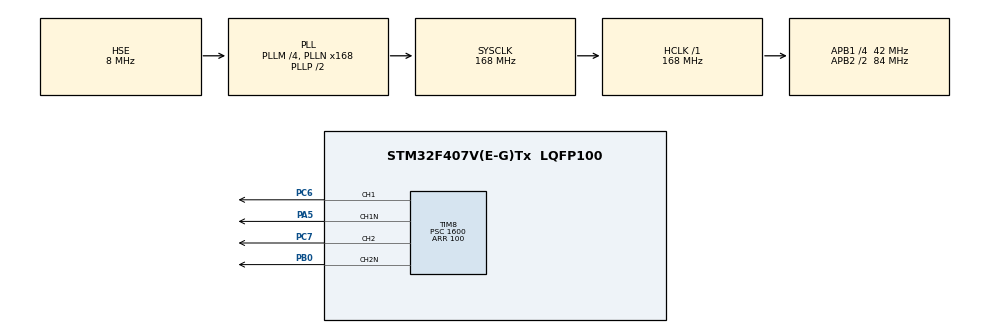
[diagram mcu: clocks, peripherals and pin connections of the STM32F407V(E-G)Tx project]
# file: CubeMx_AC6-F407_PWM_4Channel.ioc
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Mcu.Family=STM32F4
Mcu.Name=STM32F407V(E-G)Tx
Mcu.Package=LQFP100
NVIC.PriorityGroup=NVIC_PRIORITYGROUP_4
PA5.GPIO_Speed=GPIO_SPEED_FREQ_HIGH
PA5.Mode=PWM Generation1 CH1 CH1N
PA5.Signal=TIM8_CH1N
PB0.GPIO_Speed=GPIO_SPEED_FREQ_HIGH
PB0.Mode=PWM Generation2 CH2 CH2N
PB0.Signal=TIM8_CH2N
PC6.GPIO_Speed=GPIO_SPEED_FREQ_HIGH
PC6.Signal=S_TIM8_CH1
PC7.GPIO_Speed=GPIO_SPEED_FREQ_HIGH
PC7.Signal=S_TIM8_CH2
PH0-OSC_IN.Mode=HSE-External-Oscillator
PH0-OSC_IN.Signal=RCC_OSC_IN
PH1-OSC_OUT.Mode=HSE-External-Oscillator
PH1-OSC_OUT.Signal=RCC_OSC_OUT
ProjectManager.HeapSize=0x200
ProjectManager.StackSize=0x400
ProjectManager.TargetToolchain=SW4STM32
RCC.48MHZClocksFreq_Value=84000000
RCC.AHBFreq_Value=168000000
RCC.APB1CLKDivider=RCC_HCLK_DIV4
RCC.APB1Freq_Value=42000000
RCC.APB1TimFreq_Value=84000000
RCC.APB2CLKDivider=RCC_HCLK_DIV2
RCC.APB2Freq_Value=84000000
RCC.APB2TimFreq_Value=168000000
RCC.CortexFreq_Value=168000000
RCC.HCLKFreq_Value=168000000
RCC.HSE_VALUE=8000000
RCC.HSI_VALUE=16000000
RCC.LSE_VALUE=32768
RCC.PLLM=4
RCC.PLLN=168
RCC.PLLSourceVirtual=RCC_PLLSOURCE_HSE
RCC.SYSCLKFreq_VALUE=168000000
RCC.SYSCLKSource=RCC_SYSCLKSOURCE_PLLCLK
RCC.VCOOutputFreq_Value=336000000
SH.S_TIM8_CH1.0=TIM8_CH1,PWM Generation1 CH1 CH1N
SH.S_TIM8_CH2.0=TIM8_CH2,PWM Generation2 CH2 CH2N
TIM8.Channel-PWM\ Generation2\ CH2\ CH2N=TIM_CHANNEL_2
TIM8.DeadTime=255
TIM8.OCNPolarity_1=TIM_OCNPOLARITY_HIGH
TIM8.Period=100
TIM8.Prescaler=1600
TIM8.Pulse-PWM\ Generation1\ CH1\ CH1N=30
TIM8.Pulse-PWM\ Generation2\ CH2\ CH2N=80
board=CubeMx_AC6-F407_PWM_4Channel

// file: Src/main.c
/**
  ******************************************************************************
  * File Name          : main.c
  * Description        : Main program body
  ******************************************************************************
  *
  * COPYRIGHT(c) 2017 STMicroelectronics
  *
  * Redistribution and use in source and binary forms, with or without modification,
  * are permitted provided that the following conditions are met:
  *   1. Redistributions of source code must retain the above copyright notice,
  *      this list of conditions and the following disclaimer.
  *   2. Redistributions in binary form must reproduce the above copyright notice,
  *      this list of conditions and the following disclaimer in the documentation
  *      and/or other materials provided with the distribution.
  *   3. Neither the name of STMicroelectronics nor the names of its contributors
  *      may be used to endorse or promote products derived from this software
  *      without specific prior written permission.
  *
  * THIS SOFTWARE IS PROVIDED BY THE COPYRIGHT HOLDERS AND CONTRIBUTORS "AS IS"
  * AND ANY EXPRESS OR IMPLIED WARRANTIES, INCLUDING, BUT NOT LIMITED TO, THE
  * IMPLIED WARRANTIES OF MERCHANTABILITY AND FITNESS FOR A PARTICULAR PURPOSE ARE
  * DISCLAIMED. IN NO EVENT SHALL THE COPYRIGHT HOLDER OR CONTRIBUTORS BE LIABLE
  * FOR ANY DIRECT, INDIRECT, INCIDENTAL, SPECIAL, EXEMPLARY, OR CONSEQUENTIAL
  * DAMAGES (INCLUDING, BUT NOT LIMITED TO, PROCUREMENT OF SUBSTITUTE GOODS OR
  * SERVICES; LOSS OF USE, DATA, OR PROFITS; OR BUSINESS INTERRUPTION) HOWEVER
  * CAUSED AND ON ANY THEORY OF LIABILITY, WHETHER IN CONTRACT, STRICT LIABILITY,
  * OR TORT (INCLUDING NEGLIGENCE OR OTHERWISE) ARISING IN ANY WAY OUT OF THE USE
  * OF THIS SOFTWARE, EVEN IF ADVISED OF THE POSSIBILITY OF SUCH DAMAGE.
  *
  ******************************************************************************
  */
#include "main.h"
#include "stm32f4xx_hal.h"

TIM_HandleTypeDef htim8;

/* USER CODE BEGIN PV */
/* Private variables ---------------------------------------------------------*/

/* USER CODE END PV */

void SystemClock_Config(void);
void Error_Handler(void);
static void MX_GPIO_Init(void);
static void MX_TIM8_Init(void);
void HAL_TIM_MspPostInit(TIM_HandleTypeDef *htim);

/* USER CODE BEGIN PFP */
/* Private function prototypes -----------------------------------------------*/

/* USER CODE END PFP */

int main(void)
{

  /* MCU Configuration----------------------------------------------------------*/

  /* Reset of all peripherals, Initializes the Flash interface and the Systick. */
  HAL_Init();

  /* Configure the system clock */
  SystemClock_Config();

  /* Initialize all configured peripherals */
  MX_GPIO_Init();
  MX_TIM8_Init();

  /* USER CODE BEGIN 2 */

  HAL_TIM_PWM_Start(&htim8, TIM_CHANNEL_1);    //starts PWM on CH1 pin
  HAL_TIMEx_PWMN_Start(&htim8, TIM_CHANNEL_1); //starts PWM on CH1N pin
  HAL_TIM_PWM_Start(&htim8, TIM_CHANNEL_2);    //starts PWM on CH1 pin
  HAL_TIMEx_PWMN_Start(&htim8, TIM_CHANNEL_2); //starts PWM on CH1N pin

  /* USER CODE END 2 */

  /* Infinite loop */
  while (1)
  {

  }

}

/** System Clock Configuration
*/
void SystemClock_Config(void)
{

  RCC_OscInitTypeDef RCC_OscInitStruct;
  RCC_ClkInitTypeDef RCC_ClkInitStruct;

    /**Configure the main internal regulator output voltage
    */
  __HAL_RCC_PWR_CLK_ENABLE();

  __HAL_PWR_VOLTAGESCALING_CONFIG(PWR_REGULATOR_VOLTAGE_SCALE1);

    /**Initializes the CPU, AHB and APB busses clocks
    */
  RCC_OscInitStruct.OscillatorType = RCC_OSCILLATORTYPE_HSE;
  RCC_OscInitStruct.HSEState = RCC_HSE_ON;
  RCC_OscInitStruct.PLL.PLLState = RCC_PLL_ON;
  RCC_OscInitStruct.PLL.PLLSource = RCC_PLLSOURCE_HSE;
  RCC_OscInitStruct.PLL.PLLM = 4;
  RCC_OscInitStruct.PLL.PLLN = 168;
  RCC_OscInitStruct.PLL.PLLP = RCC_PLLP_DIV2;
  RCC_OscInitStruct.PLL.PLLQ = 4;
  if (HAL_RCC_OscConfig(&RCC_OscInitStruct) != HAL_OK)
  {
    Error_Handler();
  }

    /**Initializes the CPU, AHB and APB busses clocks
    */
  RCC_ClkInitStruct.ClockType = RCC_CLOCKTYPE_HCLK|RCC_CLOCKTYPE_SYSCLK
                              |RCC_CLOCKTYPE_PCLK1|RCC_CLOCKTYPE_PCLK2;
  RCC_ClkInitStruct.SYSCLKSource = RCC_SYSCLKSOURCE_PLLCLK;
  RCC_ClkInitStruct.AHBCLKDivider = RCC_SYSCLK_DIV1;
  RCC_ClkInitStruct.APB1CLKDivider = RCC_HCLK_DIV4;
  RCC_ClkInitStruct.APB2CLKDivider = RCC_HCLK_DIV2;

  if (HAL_RCC_ClockConfig(&RCC_ClkInitStruct, FLASH_LATENCY_5) != HAL_OK)
  {
    Error_Handler();
  }

    /**Configure the Systick interrupt time
    */
  HAL_SYSTICK_Config(HAL_RCC_GetHCLKFreq()/1000);

    /**Configure the Systick
    */
  HAL_SYSTICK_CLKSourceConfig(SYSTICK_CLKSOURCE_HCLK);

  /* SysTick_IRQn interrupt configuration */
  HAL_NVIC_SetPriority(SysTick_IRQn, 0, 0);
}

/* TIM8 init function */
static void MX_TIM8_Init(void)
{

  TIM_MasterConfigTypeDef sMasterConfig;
  TIM_OC_InitTypeDef sConfigOC;
  TIM_BreakDeadTimeConfigTypeDef sBreakDeadTimeConfig;

  htim8.Instance = TIM8;
  htim8.Init.Prescaler = 1600;
  htim8.Init.CounterMode = TIM_COUNTERMODE_UP;
  htim8.Init.Period = 100;
  htim8.Init.ClockDivision = TIM_CLOCKDIVISION_DIV1;
  htim8.Init.RepetitionCounter = 0;
  if (HAL_TIM_PWM_Init(&htim8) != HAL_OK)
  {
    Error_Handler();
  }

  sMasterConfig.MasterOutputTrigger = TIM_TRGO_RESET;
  sMasterConfig.MasterSlaveMode = TIM_MASTERSLAVEMODE_DISABLE;
  if (HAL_TIMEx_MasterConfigSynchronization(&htim8, &sMasterConfig) != HAL_OK)
  {
    Error_Handler();
  }

  sConfigOC.OCMode = TIM_OCMODE_PWM1;
  sConfigOC.Pulse = 30;
  sConfigOC.OCPolarity = TIM_OCPOLARITY_HIGH;
  sConfigOC.OCNPolarity = TIM_OCNPOLARITY_HIGH;
  sConfigOC.OCFastMode = TIM_OCFAST_DISABLE;
  sConfigOC.OCIdleState = TIM_OCIDLESTATE_RESET;
  sConfigOC.OCNIdleState = TIM_OCNIDLESTATE_RESET;
  if (HAL_TIM_PWM_ConfigChannel(&htim8, &sConfigOC, TIM_CHANNEL_1) != HAL_OK)
  {
    Error_Handler();
  }

  sConfigOC.Pulse = 80;
  if (HAL_TIM_PWM_ConfigChannel(&htim8, &sConfigOC, TIM_CHANNEL_2) != HAL_OK)
  {
    Error_Handler();
  }

  sBreakDeadTimeConfig.OffStateRunMode = TIM_OSSR_DISABLE;
  sBreakDeadTimeConfig.OffStateIDLEMode = TIM_OSSI_DISABLE;
  sBreakDeadTimeConfig.LockLevel = TIM_LOCKLEVEL_OFF;
  sBreakDeadTimeConfig.DeadTime = 255;
  sBreakDeadTimeConfig.BreakState = TIM_BREAK_DISABLE;
  sBreakDeadTimeConfig.BreakPolarity = TIM_BREAKPOLARITY_HIGH;
  sBreakDeadTimeConfig.AutomaticOutput = TIM_AUTOMATICOUTPUT_DISABLE;
  if (HAL_TIMEx_ConfigBreakDeadTime(&htim8, &sBreakDeadTimeConfig) != HAL_OK)
  {
    Error_Handler();
  }

  HAL_TIM_MspPostInit(&htim8);

}

/** Configure pins as
        * Analog
        * Input
        * Output
        * EVENT_OUT
        * EXTI
*/
static void MX_GPIO_Init(void)
{

  /* GPIO Ports Clock Enable */
  __HAL_RCC_GPIOH_CLK_ENABLE();
  __HAL_RCC_GPIOA_CLK_ENABLE();
  __HAL_RCC_GPIOB_CLK_ENABLE();
  __HAL_RCC_GPIOC_CLK_ENABLE();

}

void Error_Handler(void)
{
  while(1)
  {
  }
}

/************************ (C) COPYRIGHT STMicroelectronics *****END OF FILE****/
